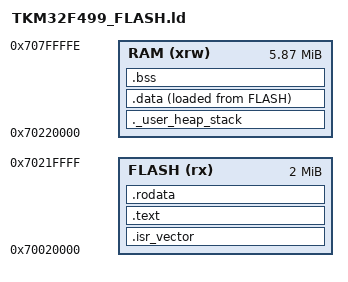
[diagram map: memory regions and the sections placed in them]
/*
*****************************************************************************
**

**  File        : LinkerScript.ld
**
**  Abstract    : Linker script for STM32F405VGTx Device with
**                1024KByte FLASH, 128KByte RAM
**
**                Set heap size, stack size and stack location according
**                to application requirements.
**
**                Set memory bank area and size if external memory is used.
**
**  Target      : STMicroelectronics STM32
**
**
**  Distribution: The file is distributed as is, without any warranty
**                of any kind.
**
*****************************************************************************
** @attention
**
** <h2><center>&copy; COPYRIGHT(c) 2014 Ac6</center></h2>
**
** Redistribution and use in source and binary forms, with or without modification,
** are permitted provided that the following conditions are met:
**   1. Redistributions of source code must retain the above copyright notice,
**      this list of conditions and the following disclaimer.
**   2. Redistributions in binary form must reproduce the above copyright notice,
**      this list of conditions and the following disclaimer in the documentation
**      and/or other materials provided with the distribution.
**   3. Neither the name of Ac6 nor the names of its contributors
**      may be used to endorse or promote products derived from this software
**      without specific prior written permission.
**
** THIS SOFTWARE IS PROVIDED BY THE COPYRIGHT HOLDERS AND CONTRIBUTORS "AS IS"
** AND ANY EXPRESS OR IMPLIED WARRANTIES, INCLUDING, BUT NOT LIMITED TO, THE
** IMPLIED WARRANTIES OF MERCHANTABILITY AND FITNESS FOR A PARTICULAR PURPOSE ARE
** DISCLAIMED. IN NO EVENT SHALL THE COPYRIGHT HOLDER OR CONTRIBUTORS BE LIABLE
** FOR ANY DIRECT, INDIRECT, INCIDENTAL, SPECIAL, EXEMPLARY, OR CONSEQUENTIAL
** DAMAGES (INCLUDING, BUT NOT LIMITED TO, PROCUREMENT OF SUBSTITUTE GOODS OR
** SERVICES; LOSS OF USE, DATA, OR PROFITS; OR BUSINESS INTERRUPTION) HOWEVER
** CAUSED AND ON ANY THEORY OF LIABILITY, WHETHER IN CONTRACT, STRICT LIABILITY,
** OR TORT (INCLUDING NEGLIGENCE OR OTHERWISE) ARISING IN ANY WAY OUT OF THE USE
** OF THIS SOFTWARE, EVEN IF ADVISED OF THE POSSIBILITY OF SUCH DAMAGE.
**
*****************************************************************************
*/

/* Entry Point */
ENTRY(Reset_Handler)

/* Highest address of the user mode stack */
_estack = 0x70220800;    /* end of RAM */
/* Generate a link error if heap and stack don't fit into RAM */
_Min_Heap_Size = 0x400;      /* required amount of heap  */
_Min_Stack_Size = 0x400; /* required amount of stack */

/* Specify the memory areas */
MEMORY
{
    FLASH (rx)     : ORIGIN = 0x70020000, LENGTH = 0x200000
    RAM (xrw)      : ORIGIN = 0x70220000, LENGTH = 0x5DFFFF
}

/* Define output sections */
SECTIONS
{
  /* The startup code goes first into FLASH */
  .isr_vector :
  {

    KEEP(*(.isr_vector)) /* Startup code */

  } >FLASH

  /* The program code and other data goes into FLASH */
  .text :
  {

    *(.text)           /* .text sections (code) */
    *(.text*)          /* .text* sections (code) */

    KEEP (*(.init))
    KEEP (*(.fini))


    _etext = .;        /* define a global symbols at end of code */
  } >FLASH

  /* Constant data goes into FLASH */
  .rodata :
  {

    *(.rodata)         /* .rodata sections (constants, strings, etc.) */
    *(.rodata*)        /* .rodata* sections (constants, strings, etc.) */

  } >FLASH

  /* used by the startup to initialize data */

  /* User_heap_stack section, used to check that there is enough RAM left */
  ._user_heap_stack :
  {

    PROVIDE ( end = . );
    PROVIDE ( _end = . );
    . = . + _Min_Heap_Size;
    . = . + _Min_Stack_Size;

  } >RAM

  _sidata = LOADADDR(.data);

  /* Initialized data sections goes into RAM, load LMA copy after code */
  .data :
  {

    _sdata = .;        /* create a global symbol at data start */
    *(.data)           /* .data sections */
    *(.data*)          


    _edata = .;        /* define a global symbol at data end */
  } >RAM AT> FLASH

  /* Uninitialized data section */

  .bss :
  {
    /* This is used by the startup in order to initialize the .bss secion */
    _sbss = .;         /* define a global symbol at bss start */
    __bss_start__ = _sbss;
    *(.bss)
    *(.bss*)
    *(COMMON)

    _ebss = .;         /* define a global symbol at bss end */
    __bss_end__ = _ebss;
  } >RAM

}
